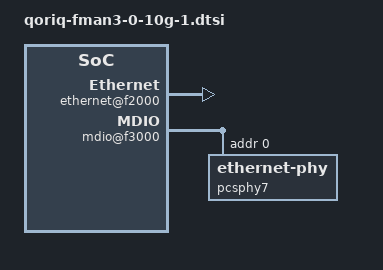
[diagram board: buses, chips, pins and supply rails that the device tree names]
// SPDX-License-Identifier: (GPL-2.0+ OR BSD-3-Clause)
/*
 * QorIQ FMan v3 10g port #1 device tree
 *
 * Copyright 2012-2015 Freescale Semiconductor Inc.
 *
 */

fman@1a00000 {
	fman0_rx_0x11: port@91000 {
		cell-index = <0x11>;
		compatible = "fsl,fman-v3-port-rx";
		reg = <0x91000 0x1000>;
		fsl,fman-10g-port;
	};

	fman0_tx_0x31: port@b1000 {
		cell-index = <0x31>;
		compatible = "fsl,fman-v3-port-tx";
		reg = <0xb1000 0x1000>;
		fsl,fman-10g-port;
	};

	ethernet@f2000 {
		cell-index = <0x9>;
		compatible = "fsl,fman-memac";
		reg = <0xf2000 0x1000>;
		fsl,fman-ports = <&fman0_rx_0x11 &fman0_tx_0x31>;
		pcsphy-handle = <&pcsphy7>;
	};

	mdio@f3000 {
		#address-cells = <1>;
		#size-cells = <0>;
		compatible = "fsl,fman-memac-mdio", "fsl,fman-xmdio";
		reg = <0xf3000 0x1000>;

		pcsphy7: ethernet-phy@0 {
			reg = <0x0>;
		};
	};
};
